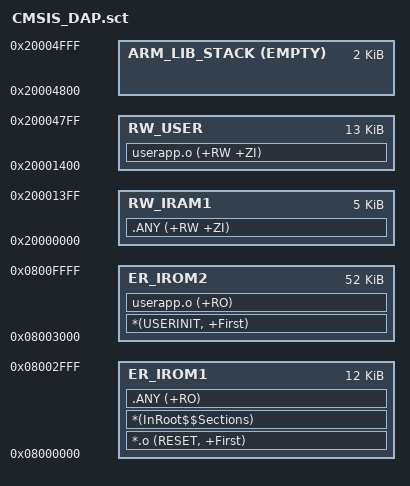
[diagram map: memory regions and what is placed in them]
LR_IROM1 0x08000000 0x00010000
{
	ER_IROM1 0x08000000 0x0003000
	{	; load address = execution address
		*.o (RESET, +First)
		*(InRoot$$Sections)
		.ANY (+RO)
	}

	ARM_LIB_STACK 0x20005000 EMPTY -0x800
	{ }
	RW_IRAM1 0x20000000 0x1400
	{	; RW data
		.ANY (+RW +ZI)
	}
	RW_USER  0x20001400 0x5000-0x800-0x1400
	{
		userapp.o (+RW +ZI)
	}
}

LR_IROM2 0x08003000 0x0000D000
{
	ER_IROM2 0x08003000 0x0000D000
	{
		*(USERINIT, +First)
		userapp.o (+RO)
	}
}
